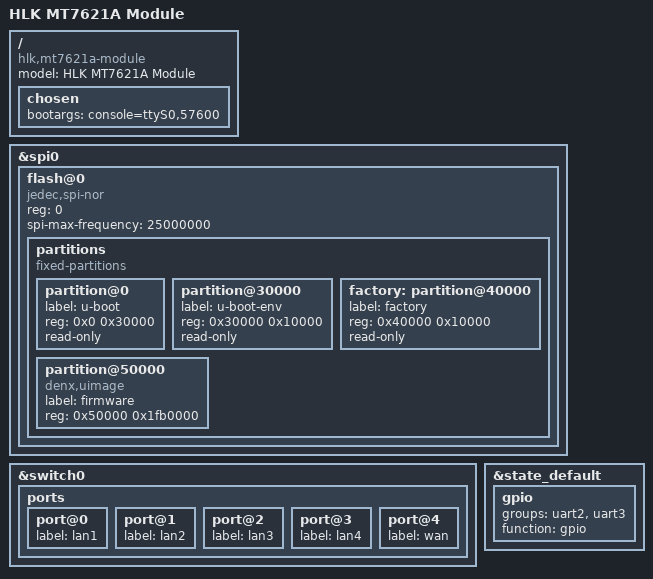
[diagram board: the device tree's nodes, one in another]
/dts-v1/;

#include "mt7621.dtsi"

/ {
	compatible = "hlk,mt7621a-module", "mediatek,mt7621-soc";
	model = "HLK MT7621A Module";

	chosen {
		bootargs = "console=ttyS0,57600";
	};
};

&spi0 {
	status = "okay";

	flash@0 {
		compatible = "jedec,spi-nor";
		reg = <0>;
		spi-max-frequency = <25000000>;

		partitions {
			compatible = "fixed-partitions";
			#address-cells = <1>;
			#size-cells = <1>;

			partition@0 {
				label = "u-boot";
				reg = <0x0 0x30000>;
				read-only;
			};

			partition@30000 {
				label = "u-boot-env";
				reg = <0x30000 0x10000>;
				read-only;
			};

			factory: partition@40000 {
				label = "factory";
				reg = <0x40000 0x10000>;
				read-only;
			};

			partition@50000 {
				compatible = "denx,uimage";
				label = "firmware";
				reg = <0x50000 0x1fb0000>;
			};
		};
	};
};

&switch0 {
	ports {
		port@0 {
			status = "okay";
			label = "lan1";
		};

		port@1 {
			status = "okay";
			label = "lan2";
		};

		port@2 {
			status = "okay";
			label = "lan3";
		};

		port@3 {
			status = "okay";
			label = "lan4";
		};

		port@4 {
			status = "okay";
			label = "wan";
		};
	};
};

&state_default {
	gpio {
		groups = "uart2", "uart3";
		function = "gpio";
	};
};
